VERSION ""

NS_ :

BS_:

BU_: DASH_SENSORS

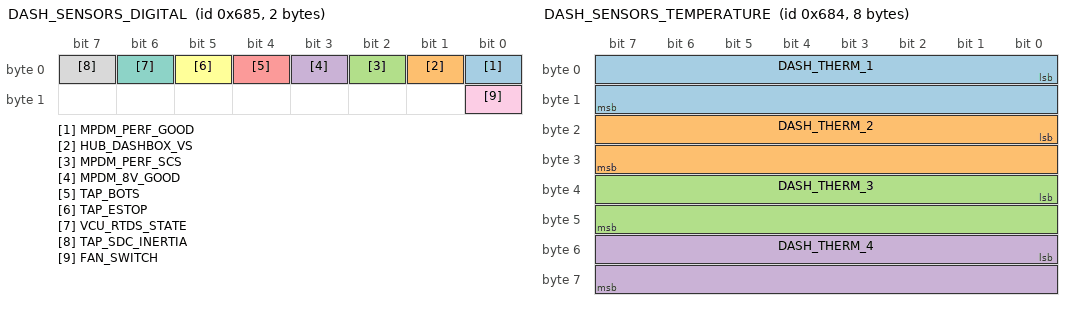
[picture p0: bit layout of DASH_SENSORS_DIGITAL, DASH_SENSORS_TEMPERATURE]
BO_ 1669 DASH_SENSORS_DIGITAL: 2 DASH_SENSORS
 SG_ MPDM_PERF_GOOD : 0|1@1+ (1,0) [0|1] "bool" Vector__XXX
 SG_ HUB_DASHBOX_VS : 1|1@1+ (1,0) [0|1] "bool" Vector__XXX
 SG_ MPDM_PERF_SCS : 2|1@1+ (1,0) [0|1] "bool" Vector__XXX
 SG_ MPDM_8V_GOOD : 3|1@1+ (1,0) [0|1] "bool" Vector__XXX
 SG_ TAP_BOTS : 4|1@1+ (1,0) [0|1] "bool" Vector__XXX
 SG_ TAP_ESTOP : 5|1@1+ (1,0) [0|1] "bool" Vector__XXX
 SG_ VCU_RTDS_STATE : 6|1@1+ (1,0) [0|1] "bool" Vector__XXX
 SG_ TAP_SDC_INERTIA : 7|1@1+ (1,0) [0|1] "bool" Vector__XXX
 SG_ FAN_SWITCH : 8|1@1+ (1,0) [0|1] "bool" Vector__XXX

BO_ 1668 DASH_SENSORS_TEMPERATURE: 8 DASH_SENSORS
 SG_ DASH_THERM_1 : 0|16@1- (0.1,0) [-40|125] "degC" Vector__XXX
 SG_ DASH_THERM_2 : 16|16@1- (0.1,0) [-40|125] "degC" Vector__XXX
 SG_ DASH_THERM_3 : 32|16@1- (0.1,0) [-40|125] "degC" Vector__XXX
 SG_ DASH_THERM_4 : 48|16@1- (0.1,0) [-40|125] "degC" Vector__XXX

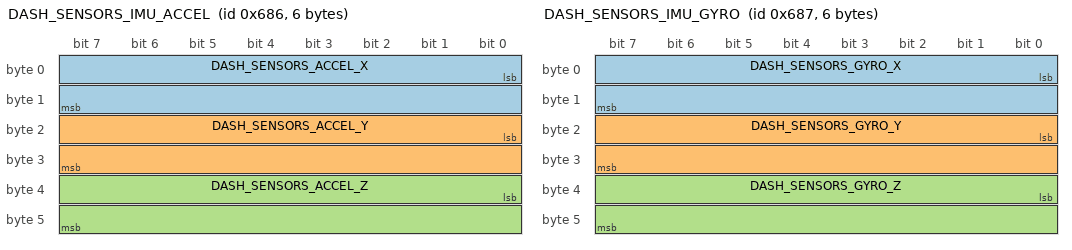
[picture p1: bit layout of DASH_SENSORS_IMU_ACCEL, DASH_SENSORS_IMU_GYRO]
BO_ 1670 DASH_SENSORS_IMU_ACCEL: 6 DASH_SENSORS
 SG_ DASH_SENSORS_ACCEL_X : 0|16@1- (0.000122,0) [-4|4] "g" Vector__XXX
 SG_ DASH_SENSORS_ACCEL_Y : 16|16@1- (0.000122,0) [-4|4] "g" Vector__XXX
 SG_ DASH_SENSORS_ACCEL_Z : 32|16@1- (0.000122,0) [-4|4] "g" Vector__XXX

BO_ 1671 DASH_SENSORS_IMU_GYRO: 6 DASH_SENSORS
 SG_ DASH_SENSORS_GYRO_X : 0|16@1- (0.0175,0) [-500|500] "dps" Vector__XXX
 SG_ DASH_SENSORS_GYRO_Y : 16|16@1- (0.0175,0) [-500|500] "dps" Vector__XXX
 SG_ DASH_SENSORS_GYRO_Z : 32|16@1- (0.0175,0) [-500|500] "dps" Vector__XXX

BO_ 1672 DASH_SENSORS_TEMP: 4 DASH_SENSORS
 SG_ DASH_SENSORS_IMU_TEMP : 0|16@1- (0.00390625,25) [-40|85] "degC" Vector__XXX
 SG_ DASH_SENSORS_AMBIENT_TEMP : 16|16@1- (0.0625,0) [-55|125] "degC" Vector__XXX

BO_ 1673 DASH_SENSORS_STATUS: 1 DASH_SENSORS
 SG_ DASH_SENSORS_ISM330_OK : 0|1@1+ (1,0) [0|1] "" Vector__XXX
 SG_ DASH_SENSORS_MCP9800_OK : 1|1@1+ (1,0) [0|1] "" Vector__XXX
